# M480_v1 register map
File version: 1.0
Registers are 32-bit, read-write, reset 0x0 unless marked. A register's access mark holds for its fields unless they carry their own. Offsets are from the block's base; [hi:lo] are bit positions; 'fields as' and 'values as' point back to an identical list.

## EMAC (part 2 of 2) — EMAC Register Map
Base 0x4000B000
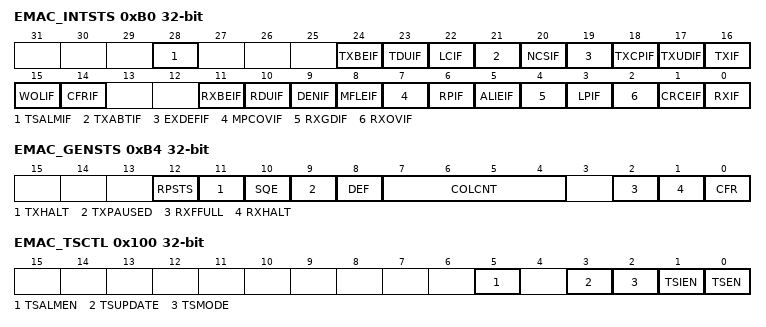
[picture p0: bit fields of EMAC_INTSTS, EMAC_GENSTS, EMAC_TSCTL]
0xB0 EMAC_INTSTS — MAC Interrupt Status Register
  [28] TSALMIF — Time Stamp Alarm Interrupt. The TSALMIF high indicates the EMAC_TSSEC register value equals to EMAC_ALMSEC register and EMAC_TSSUBSEC register value equals to register EMAC_ALMSUBSEC. If TSALMIF is high and TSALMIEN (EMAC_INTEN[28]) enabled, the TXIF will be high. Write 1 to this bit clears the TSALMIF status.
    0=EMAC_TSSEC did not equal EMAC_ALMSEC or EMAC_TSSUBSEC did not equal EMAC_ALMSUBSEC; 1=EMAC_TSSEC equals EMAC_ALMSEC and EMAC_TSSUBSEC equals EMAC_ALMSUBSEC
  [24] TXBEIF — Transmit Bus Error Interrupt. The TXBEIF high indicates the memory controller replies ERROR response while EMAC access system memory through TXDMA during packet transmission process. Reset EMAC is recommended while TXBEIF status is high. If the TXBEIF is high and TXBEIEN (EMAC_INTEN[24]) is enabled, the TXIF will be high. Write 1 to this bit clears the TXBEIF status.
    0=No ERROR response is received; 1=ERROR response is received
  [23] TDUIF — Transmit Descriptor Unavailable Interrupt. The TDUIF high indicates that there is no available TX descriptor for packet transmission and TXDMA will stay at Halt state. Once, the TXDMA enters the Halt state, S/W must issues a write command to TSDR register to make TXDMA leave Halt state while new TX descriptor is available. If the TDUIF is high and TDUIEN (EMAC_INTEN[23]) is enabled, the TXIF will be high. Write 1 to this bit clears the TDUIF status.
    0=TX descriptor is available; 1=TX descriptor is unavailable
  [22] LCIF — Late Collision Interrupt. The LCIF high indicates the collision occurred in the outside of 64 bytes collision window. This means after the 64 bytes of a frame has been transmitted out to the network, the collision still occurred. The late collision check will only be done while EMAC is operating on half-duplex mode. If the LCIF is high and LCIEN (EMAC_INTEN[22]) is enabled, the TXIF will be high. Write 1 to this bit clears the LCIF status.
    0=No collision occurred in the outside of 64 bytes collision window; 1=Collision occurred in the outside of 64 bytes collision window
  [21] TXABTIF — Transmit Abort Interrupt. The TXABTIF high indicates the packet incurred 16 consecutive collisions during transmission, and then the transmission process for this packet is aborted. The transmission abort is only available while EMAC is operating on half-duplex mode. If the TXABTIF is high and TXABTIEN (EMAC_INTEN[21]) is enabled, the TXIF will be high. Write 1 to this bit clears the TXABTIF status.
    0=Packet does not incur 16 consecutive collisions during transmission; 1=Packet incurred 16 consecutive collisions during transmission
  [20] NCSIF — No Carrier Sense Interrupt. The NCSIF high indicates the MII I/F signal CRS does not active at the start of or during the packet transmission. The NCSIF is only available while EMAC is operating on half-duplex mode. If the NCSIF is high and NCSIEN (EMAC_INTEN[20]) is enabled, the TXIF will be high. Write 1 to this bit clears the NCSIF status.
    0=CRS signal actives correctly; 1=CRS signal does not active at the start of or during the packet transmission
  [19] EXDEFIF — Defer Exceed Interrupt. The EXDEFIF high indicates the frame waiting for transmission has deferred over 0.32768ms on 100Mbps mode, or 3.2768ms on 10Mbps mode. The deferral exceed check will only be done while bit NODEF of MCMDR is disabled, and EMAC is operating on half-duplex mode. If the EXDEFIF is high and EXDEFIEN (EMAC_INTEN[19]) is enabled, the TXIF will be high. Write 1 to this bit clears the EXDEFIF status.
    0=Frame waiting for transmission has not deferred over 0.32768ms (100Mbps) or 3.2768ms (10Mbps); 1=Frame waiting for transmission has deferred over 0.32768ms (100Mbps) or 3.2768ms (10Mbps)
  [18] TXCPIF — Transmit Completion Interrupt. The TXCPIF indicates the packet transmission has completed correctly. If the TXCPIF is high and TXCPIEN (EMAC_INTEN[18]) is enabled, the TXIF will be high. Write 1 to this bit clears the TXCPIF status.
    0=The packet transmission not completed; 1=The packet transmission has completed
  [17] TXUDIF — Transmit FIFO Underflow Interrupt. The TXUDIF high indicates the TXFIFO underflow occurred during packet transmission. While the TXFIFO underflow occurred, the EMAC will retransmit the packet automatically without S/W intervention. If the TXFIFO underflow occurred often, it is recommended that modify TXFIFO threshold control, the TXFIFOTH of FFTCR register, to higher level. If the TXUDIF is high and TXUDIEN (EMAC_INTEN[17]) is enabled, the TXIF will be high. Write 1 to this bit clears the TXUDIF status.
    0=No TXFIFO underflow occurred during packet transmission; 1=TXFIFO underflow occurred during packet transmission
  [16] TXIF — Transmit Interrupt. The TXIF indicates the TX interrupt status. If TXIF high and its corresponding enable bit, TXIEN (EMAC_INTEN[16]), is also high indicates the EMAC generates TX interrupt to CPU. If TXIF is high but TXIEN (EMAC_INTEN[16]) is disabled, no TX interrupt is generated. The TXIF is logic OR result of bit logic AND result of EMAC_INTSTS[28:17] and EMAC_INTEN[28:17]. In other words, if any bit of EMAC_INTSTS[28:17] is high and its corresponding enable bit in EMAC_INTEN[28:17] is also enabled, the TXIF will be high. Because the TXIF is a logic OR result, clears EMAC_INTSTS[28:17] makes TXIF be cleared, too.
    0=No status bit in EMAC_INTSTS[28:17] is set or no enable bit in EMAC_INTEN[28:17] is enabled; 1=At least one status in EMAC_INTSTS[28:17] is set and its corresponding enable bit in EMAC_INTEN[28:17] is enabled, too
  [15] WOLIF — Wake on LAN Interrupt Flag. The WOLIF high indicates EMAC receives a Magic Packet. The CFRIF only available while system is in Power-down mode and WOLEN is set high. If the WOLIF is high and WOLIEN (EMAC_INTEN[15]) is enabled, the RXIF will be high. Write 1 to this bit clears the WOLIF status.
    0=The EMAC does not receive the Magic Packet; 1=The EMAC receives a Magic Packet
  [14] CFRIF — Control Frame Receive Interrupt. The CFRIF high indicates EMAC receives a flow control frame. The CFRIF only available while EMAC is operating on full duplex mode. If the CFRIF is high and CFRIEN (EMAC_INTEN[14]) is enabled, the RXIF will be high. Write 1 to this bit clears the CFRIF status.
    0=The EMAC does not receive the flow control frame; 1=The EMAC receives a flow control frame
  [11] RXBEIF — Receive Bus Error Interrupt. The RXBEIF high indicates the memory controller replies ERROR response while EMAC access system memory through RXDMA during packet reception process. Reset EMAC is recommended while RXBEIF status is high. If the RXBEIF is high and RXBEIEN (EMAC_INTEN[11]) is enabled, the RXIF will be high. Write 1 to this bit clears the RXBEIF status.
    values as TXBEIF
  [10] RDUIF — Receive Descriptor Unavailable Interrupt. The RDUIF high indicates that there is no available RX descriptor for packet reception and RXDMA will stay at Halt state. Once, the RXDMA enters the Halt state, S/W must issues a write command to RSDR register to make RXDMA leave Halt state while new RX descriptor is available. If the RDUIF is high and RDUIEN (EMAC_INTEN[10]) is enabled, the RXIF will be high. Write 1 to this bit clears the RDUIF status.
    0=RX descriptor is available; 1=RX descriptor is unavailable
  [9] DENIF — DMA Early Notification Interrupt. The DENIF high indicates the EMAC has received the LENGTH field of the incoming packet. If the DENIF is high and DENIENI (EMAC_INTEN[9]) is enabled, the RXIF will be high. Write 1 to this bit clears the DENIF status.
    0=The LENGTH field of incoming packet has not received yet; 1=The LENGTH field of incoming packet has received
  [8] MFLEIF — Maximum Frame Length Exceed Interrupt Flag. The MFLEIF high indicates the length of the incoming packet has exceeded the length limitation configured in DMARFC register and the incoming packet is dropped. If the MFLEIF is high and MFLEIEN (EMAC_INTEN[8]) is enabled, the RXIF will be high. Write 1 to this bit clears the MFLEIF status.
    0=The length of the incoming packet does not exceed the length limitation configured in DMARFC; 1=The length of the incoming packet has exceeded the length limitation configured in DMARFC
  [7] MPCOVIF — Missed Packet Counter Overrun Interrupt Flag. The MPCOVIF high indicates the MPCNT, Missed Packet Count, has overflow. If the MPCOVIF is high and MPCOVIEN (EMAC_INTEN[7]) is enabled, the RXIF will be high. Write 1 to this bit clears the MPCOVIF status.
    0=The MPCNT has not rolled over yet; 1=The MPCNT has rolled over yet
  [6] RPIF — Runt Packet Interrupt. The RPIF high indicates the length of the incoming packet is less than 64 bytes and the packet is dropped. If the ARP (EMAC_CTL[2]) is set, the short packet is regarded as a good packet and RPIF will not be set. If the RPIF is high and RPIEN (EMAC_INTEN[6]) is enabled, the RXIF will be high. Write 1 to this bit clears the RPIF status.
    0=The incoming frame is not a short frame or S/W wants to receive a short frame; 1=The incoming frame is a short frame and dropped
  [5] ALIEIF — Alignment Error Interrupt. The ALIEIF high indicates the length of the incoming frame is not a multiple of byte. If the ALIEIF is high and ALIEIEN (EMAC_INTEN[5]) is enabled, the RXIF will be high. Write 1 to this bit clears the ALIEIF status.
    0=The frame length is a multiple of byte; 1=The frame length is not a multiple of byte
  [4] RXGDIF — Receive Good Interrupt. The RXGDIF high indicates the frame reception has completed. If the RXGDIF is high and RXGDIEN (EAMC_MIEN[4]) is enabled, the RXIF will be high. Write 1 to this bit clears the RXGDIF status.
    0=The frame reception has not complete yet; 1=The frame reception has completed
  [3] LPIF — Long Packet Interrupt Flag. The LPIF high indicates the length of the incoming packet is greater than 1518 bytes and the incoming packet is dropped. If the ALP (EMAC_CTL[1]) is set, the long packet will be regarded as a good packet and LPIF will not be set. If the LPIF is high and LPIEN (EMAC_INTEN[3]) is enabled, the RXIF will be high. Write 1 to this bit clears the LPIF status.
    0=The incoming frame is not a long frame or S/W wants to receive a long frame; 1=The incoming frame is a long frame and dropped
  [2] RXOVIF — Receive FIFO Overflow Interrupt. The RXOVIF high indicates the RXFIFO overflow occurred during packet reception. While the RXFIFO overflow occurred, the EMAC drops the current receiving packer. If the RXFIFO overflow occurred often, it is recommended that modify RXFIFO threshold control, the RXFIFOTH of FFTCR register, to higher level. If the RXOVIF is high and RXOVIEN (EMAC_INTEN[2]) is enabled, the RXIF will be high. Write 1 to this bit clears the RXOVIF status.
    0=No RXFIFO overflow occurred during packet reception; 1=RXFIFO overflow occurred during packet reception
  [1] CRCEIF — CRC Error Interrupt. The CRCEIF high indicates the incoming packet incurred the CRC error and the packet is dropped. If the AEP (EMAC_CTL[4]) is set, the CRC error packet will be regarded as a good packet and CRCEIF will not be set. If the CRCEIF is high and CRCEIEN (EMAC_INTEN[1]) is enabled, the RXIF will be high. Write 1 to this bit clears the CRCEIF status.
    0=The frame does not incur CRC error; 1=The frame incurred CRC error
  [0] RXIF — Receive Interrupt. The RXIF indicates the RX interrupt status. If RXIF high and its corresponding enable bit, RXIEN (EMAC_INTEN[0]), is also high indicates the EMAC generates RX interrupt to CPU. If RXIF is high but RXIEN (EMAC_INTEN[0]) is disabled, no RX interrupt is generated. The RXIF is logic OR result of bit logic AND result of EMAC_INTSTS[15:1] and EMAC_INTEN[15:1]. In other words, if any bit of EMAC_INTSTS[15:1] is high and its corresponding enable bit in EMAC_INTEN[15:1] is also enabled, the RXIF will be high. Because the RXIF is a logic OR result, clears EMAC_INTSTS[15:1] makes RXIF be cleared, too.
    0=No status bit in EMAC_INTSTS[15:1] is set or no enable bit in EMAC_INTEN[15:1] is enabled; 1=At least one status in EMAC_INTSTS[15:1] is set and its corresponding enable bit in EMAC_INTEN[15:1] is enabled, too
0xB4 EMAC_GENSTS — MAC General Status Register
  [12] RPSTS — Remote Pause Status. The RPSTS indicates that remote pause counter down counting actives. After Ethernet MAC controller sent PAUSE frame out successfully, it starts the remote pause counter down counting. When this bit high, it's predictable that remote Ethernet MAC controller wouldn't start the packet transmission until the down counting done.
    0=Remote pause counter down counting done; 1=Remote pause counter down counting actives
  [11] TXHALT — Transmission Halted. The TXHALT high indicates the next normal packet transmission process will be halted because the bit TXON (EMAC_CTL[8]) is disabled be S/W.
    0=Next normal packet transmission process will go on; 1=Next normal packet transmission process will be halted
  [10] SQE — Signal Quality Error. The SQE high indicates the SQE error found at end of packet transmission on 10Mbps half-duplex mode. The SQE error check will only be done while both bit SQECHKEN (EMAC_CTL[17]) is enabled and EMAC is operating on 10Mbps half-duplex mode.
    0=No SQE error found at end of packet transmission; 1=SQE error found at end of packet transmission
  [9] TXPAUSED — Transmission Paused. The TXPAUSED high indicates the next normal packet transmission process will be paused temporally because EMAC received a PAUSE control frame.
    0=Next normal packet transmission process will go on; 1=Next normal packet transmission process will be paused
  [8] DEF — Deferred Transmission. The DEF high indicates the packet transmission has deferred once. The DEF is only available while EMAC is operating on half-duplex mode.
    0=Packet transmission does not defer; 1=Packet transmission has deferred once
  [7:4] COLCNT — Collision Count. The COLCNT indicates that how many collisions occurred consecutively during a packet transmission. If the packet incurred 16 consecutive collisions during transmission, the COLCNT will be 4 h0 and bit TXABTIF will be set to 1.
  [2] RXFFULL — RXFIFO Full. The RXFFULL indicates the RXFIFO is full due to four 64-byte packets are kept in RXFIFO and the following incoming packet will be dropped.
    0=The RXFIFO is not full; 1=The RXFIFO is full and the following incoming packet will be dropped
  [1] RXHALT — Receive Halted. The RXHALT high indicates the next normal packet reception process will be halted because the bit RXON of MCMDR is disabled be S/W.
    0=Next normal packet reception process will go on; 1=Next normal packet reception process will be halted
  [0] CFR — Control Frame Received. The CFRIF high indicates EMAC receives a flow control frame. The CFRIF only available while EMAC is operating on full duplex mode.
    values as EMAC_INTSTS.CFRIF
0xB8 EMAC_MPCNT reset 0x7FFF — Missed Packet Count Register
  [15:0] MPCNT — Miss Packet Count. The MPCNT indicates the number of packets that were dropped due to various types of receive errors. The following type of receiving error makes missed packet counter increase: Incoming packet is incurred RXFIFO overflow. Incoming packet is dropped due to RXON is disabled. Incoming packet is incurred CRC error.
0xBC EMAC_RPCNT ro — MAC Receive Pause Count Register
  [15:0] RPCNT — MAC Receive Pause Count. The RPCNT keeps the OPERAND field of the PAUSE control frame. It indicates how many slot time (512-bit time) the TX of EMAC will be paused.
0xC8 EMAC_FRSTS — DMA Receive Frame Status Register
  [15:0] RXFLT — Receive Frame LENGTH. The RXFLT keeps the LENGTH field of each incoming Ethernet packet. If the bit DENIEN (EMAC_INTEN[9]) is enabled and the LENGTH field of incoming packet has received, the bit DENIF (EMAC_INTSTS[9]) will be set and trigger interrupt. And, the content of LENGTH field will be stored in RXFLT.
0xCC EMAC_CTXDSA ro — Current Transmit Descriptor Start Address Register
  [31:0] CTXDSA — Current Transmit Descriptor Start Address. The CTXDSA keeps the start address of TX descriptor that is used by TXDMA currently. The CTXDSA is read only and write to this register has no effect.
0xD0 EMAC_CTXBSA ro — Current Transmit Buffer Start Address Register
  [31:0] CTXBSA — Current Transmit Buffer Start Address. The CTXDSA keeps the start address of TX frame buffer that is used by TXDMA currently. The CTXBSA is read only and write to this register has no effect.
0xD4 EMAC_CRXDSA ro — Current Receive Descriptor Start Address Register
  [31:0] CRXDSA — Current Receive Descriptor Start Address. The CRXDSA keeps the start address of RX descriptor that is used by RXDMA currently. The CRXDSA is read only and write to this register has no effect.
0xD8 EMAC_CRXBSA ro — Current Receive Buffer Start Address Register
  [31:0] CRXBSA — Current Receive Buffer Start Address. The CRXBSA keeps the start address of RX frame buffer that is used by RXDMA currently. The CRXBSA is read only and write to this register has no effect.
0x100 EMAC_TSCTL — Time Stamp Control Register
  [5] TSALMEN — Time Stamp Alarm Enable Bit. Set this bit high enable Ethernet MAC controller to set TSALMIF (EMAC_INTSTS[28]) high when EMAC_TSSEC equals to EMAC_ALMSEC and EMAC_TSSUBSEC equals to EMAC_ALMSUBSEC.
    0=Alarm disabled when EMAC_TSSEC equals to EMAC_ALMSEC and EMAC_TSSUBSEC equals to EMAC_ALMSUBSEC; 1=Alarm enabled when EMAC_TSSEC equals to EMAC_ALMSEC and EMAC_TSSUBSEC equals to EMAC_ALMSUBSEC
  [3] TSUPDATE — Time Stamp Counter Time Update Enable Bit. Set this bit high enables Ethernet MAC controller to add value of register EMAC_UPDSEC and EMAC_UPDSUBSEC to PTP time stamp counter. After the add operation finished, Ethernet MAC controller clear this bit to low automatically.
    0=No action; 1=EMAC_UPDSEC updated to EMAC_TSSEC and EMAC_UPDSUBSEC updated to EMAC_TSSUBSEC
  [2] TSMODE — Time Stamp Fine Update Enable Bit. This bit chooses the time stamp counter update mode.
    0=Time stamp counter is in coarse update mode; 1=Time stamp counter is in fine update mode
  [1] TSIEN — Time Stamp Counter Initialization Enable Bit. Set this bit high enables Ethernet MAC controller to load value of register EMAC_UPDSEC and EMAC_UPDSUBSEC to PTP time stampe counter. After the load operation finished, Ethernet MAC controller clear this bit to low automatically.
    0=Time stamp counter initialization done; 1=Time stamp counter initialization Enabled
  [0] TSEN — Time Stamp Function Enable Bit. This bit controls if the IEEE 1588 PTP time stamp function is enabled or not. Set this bit high to enable IEEE 1588 PTP time stamp function while set this bit low to disable IEEE 1588 PTP time stamp function.
    0=I EEE 1588 PTP time stamp function Disabled; 1=IEEE 1588 PTP time stamp function Enabled
0x110 EMAC_TSSEC ro — Time Stamp Counter Second Register
  [31:0] SEC — Time Stamp Counter Second. This register reflects the bit [63:32] value of 64-bit reference timing counter. This 32-bit value is used as the second part of time stamp when TSEN (EMAC_TSCTL[0]) is high.
0x114 EMAC_TSSUBSEC ro — Time Stamp Counter Sub Second Register
  [31:0] SUBSEC — Time Stamp Counter Sub-second. This register reflects the bit [31:0] value of 64-bit reference timing counter. This 32-bit value is used as the sub-second part of time stamp when TSEN (EMAC_TSCTL[0]) is high.
0x118 EMAC_TSINC — Time Stamp Increment Register
  [7:0] CNTINC — Time Stamp Counter Increment. Time stamp counter increment value. If TSEN (EMAC_TSCTL[0]) is high, EMAC adds EMAC_TSSUBSEC with this 8-bit value every time when it wants to increase the EMAC_TSSUBSEC value.
0x11C EMAC_TSADDEND — Time Stamp Addend Register
  [31:0] ADDEND — Time Stamp Counter Addend. This register keeps a 32-bit value for accumulator to enable increment of EMAC_TSSUBSEC. If TSEN (EMAC_TSCTL[0]) and TSMODE (EMAC_TSCTL[2]) are both high, the EMAC increases accumulator with this 32-bit value in each HCLK. Once the accumulator is overflow, it generates a enable to increase EMAC_TSSUBSEC with an 8-bit value kept in register EMAC_TSINC.
0x120 EMAC_UPDSEC — Time Stamp Update Second Register
  [31:0] SEC — Time Stamp Counter Second Update. When TSIEN (EMAC_TSCTL[1]) is high, EMAC loads this 32-bit value to EMAC_TSSEC directly. When TSUPDATE (EMAC_TSCTL[3]) is high, the EMAC increases EMAC_TSSEC with this 32-bit value.
0x124 EMAC_UPDSUBSEC — Time Stamp Update Sub Second Register
  [31:0] SUBSEC — Time Stamp Counter Sub-second Update. When TSIEN (EMAC_TSCTL[1]) is high, EMAC loads this 32-bit value to EMAC_TSSUBSEC directly. When TSUPDATE (EMAC_TSCTL[3]) is high, the EMAC increases EMAC_TSSUBSEC with this 32-bit value.
0x128 EMAC_ALMSEC — Time Stamp Alarm Second Register
  [31:0] SEC — Time Stamp Counter Second Alarm. Time stamp counter second part alarm value. This value is only useful when ALMEN (EMAC_TSCTL[5]) is high. If ALMEN (EMAC_TSCTL[5]) is high, EMAC_TSSEC equals to EMAC_ALMSEC and EMAC_TSSUBSEC equals to EMAC_ALMSUBSEC, the Ethernet MAC controller sets TSALMIF (EMAC_INTSTS[28]) high.
0x12C EMAC_ALMSUBSEC — Time Stamp Alarm Sub Second Register
  [31:0] SUBSEC — Time Stamp Counter Sub-second Alarm. Time stamp counter sub-second part alarm value. This value is only useful when ALMEN (EMAC_TSCTL[5]) is high. If ALMEN (EMAC_TSCTL[5]) is high, EMAC_TSSEC equals to EMAC_ALMSEC and EMAC_TSSUBSEC equals to EMAC_ALMSUBSEC, the Ethernet MAC controller sets TSALMIF (EMAC_INTSTS[28]) high.
